# ATmega64A device description
Architecture: AVR8; Family: megaAVR
Registers are 8-bit, access not given, no defined reset value unless marked. A register's access mark holds for its fields unless they carry their own. Offsets are from the block's base; [hi:lo] are bit positions.

## USART0 — USART
Instances: USART0 0x00
0x29 UBRR0L — USART Baud Rate Register Low Byte
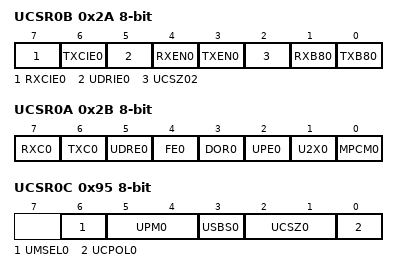
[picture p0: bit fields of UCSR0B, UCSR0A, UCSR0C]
0x2A UCSR0B — USART Control and Status Register B
  [7] RXCIE0 — RX Complete Interrupt Enable
  [6] TXCIE0 — TX Complete Interrupt Enable
  [5] UDRIE0 — USART Data register Empty Interrupt Enable
  [4] RXEN0 — Receiver Enable
  [3] TXEN0 — Transmitter Enable
  [2] UCSZ02 — Character Size
  [1] RXB80 — Receive Data Bit 8
  [0] TXB80 — Transmit Data Bit 8
0x2B UCSR0A — USART Control and Status Register A
  [7] RXC0 — USART Receive Complete
  [6] TXC0 — USART Transmitt Complete
  [5] UDRE0 — USART Data Register Empty
  [4] FE0 — Framing Error
  [3] DOR0 — Data overRun
  [2] UPE0 — Parity Error
  [1] U2X0 — Double the USART transmission speed
  [0] MPCM0 — Multi-processor Communication Mode
0x2C UDR0 — USART I/O Data Register
0x90 UBRR0H bits used 3:0 — USART Baud Rate Register Hight Byte
0x95 UCSR0C — USART Control and Status Register C
  [6] UMSEL0 — USART Mode Select
    0=Asynchronous Operation; 1=Synchronous Operation
  [5:4] UPM0 — Parity Mode Bits
    0=Disabled; 2=Enabled, Even Parity; 3=Enabled, Odd Parity
  [3] USBS0 — Stop Bit Select
    0=1-bit; 1=2-bit
  [2:1] UCSZ0 — Character Size
  [0] UCPOL0 — Clock Polarity

## USART1 — USART
Instances: USART1 0x00
0x98 UBRR1H bits used 3:0 — USART Baud Rate Register Hight Byte
0x99 UBRR1L — USART Baud Rate Register Low Byte
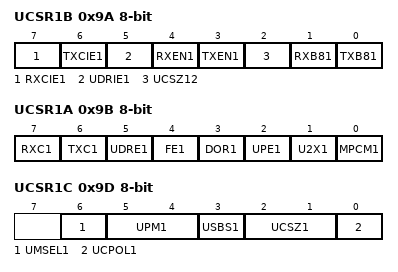
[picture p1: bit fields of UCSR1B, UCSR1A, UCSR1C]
0x9A UCSR1B — USART Control and Status Register B
  [7] RXCIE1 — RX Complete Interrupt Enable
  [6] TXCIE1 — TX Complete Interrupt Enable
  [5] UDRIE1 — USART Data register Empty Interrupt Enable
  [4] RXEN1 — Receiver Enable
  [3] TXEN1 — Transmitter Enable
  [2] UCSZ12 — Character Size
  [1] RXB81 — Receive Data Bit 8
  [0] TXB81 — Transmit Data Bit 8
0x9B UCSR1A — USART Control and Status Register A
  [7] RXC1 — USART Receive Complete
  [6] TXC1 — USART Transmitt Complete
  [5] UDRE1 — USART Data Register Empty
  [4] FE1 — Framing Error
  [3] DOR1 — Data overRun
  [2] UPE1 — Parity Error
  [1] U2X1 — Double the USART transmission speed
  [0] MPCM1 — Multi-processor Communication Mode
0x9C UDR1 — USART I/O Data Register
0x9D UCSR1C — USART Control and Status Register C
  [6] UMSEL1 — USART Mode Select
    0=Asynchronous Operation; 1=Synchronous Operation
  [5:4] UPM1 — Parity Mode Bits
    0=Disabled; 2=Enabled, Even Parity; 3=Enabled, Odd Parity
  [3] USBS1 — Stop Bit Select
    0=1-bit; 1=2-bit
  [2:1] UCSZ1 — Character Size
  [0] UCPOL1 — Clock Polarity

## CPU — CPU Registers
Instances: CPU 0x00
Parameters: CORE_VERSION=V2E
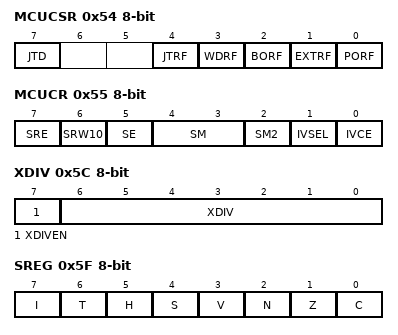
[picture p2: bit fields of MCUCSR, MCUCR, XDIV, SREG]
0x54 MCUCSR — MCU Control And Status Register
  [7] JTD — JTAG Interface Disable
  [4] JTRF — JTAG Reset Flag
  [3] WDRF — Watchdog Reset Flag
  [2] BORF — Brown-out Reset Flag
  [1] EXTRF — External Reset Flag
  [0] PORF — Power-on reset flag
0x55 MCUCR — MCU Control Register
  [7] SRE — External SRAM Enable
  [6] SRW10 — External SRAM Wait State Select
  [5] SE — Sleep Enable
  [4:3] SM — Sleep Mode Select
  [2] SM2 — Sleep Mode Select
    0=IDLE; 2=ADC (ADC Noise Reduction (If Available)); 4=PDOWN (Power Down); 6=PSAVE (Power Save); 5=STDBY (Standby); 7=ESTDBY (Extended Standby)
  [1] IVSEL — Interrupt Vector Select
  [0] IVCE — Interrupt Vector Change Enable
0x5C XDIV — XTAL Divide Control Register
  [7] XDIVEN — XTAL Divide Enable
  [6:0] XDIV — XTAl Divide Select Bits
0x5D SP 16-bit — Stack Pointer
0x5F SREG — Status Register
  [7] I — Global Interrupt Enable
  [6] T — Bit Copy Storage
  [5] H — Half Carry Flag
  [4] S — Sign Bit
  [3] V — Two's Complement Overflow Flag
  [2] N — Negative Flag
  [1] Z — Zero Flag
  [0] C — Carry Flag
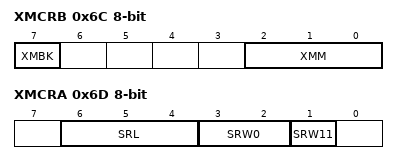
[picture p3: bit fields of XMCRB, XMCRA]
0x6C XMCRB — External Memory Control Register B
  [7] XMBK — External Memory Bus Keeper Enable
  [2:0] XMM — External Memory High Mask
0x6D XMCRA — External Memory Control Register A
  [6:4] SRL — Wait state page limit
    0=LS = N/A, US = 0x1100 - 0xFFFF; 1=LS = 0x1100 - 0x1FFF, US = 0x2000 - 0xFFFF; 2=LS = 0x1100 - 0x3FFF, US = 0x4000 - 0xFFFF; 3=LS = 0x1100 - 0x5FFF, US = 0x6000 - 0xFFFF; 4=LS = 0x1100 - 0x7FFF, US = 0x8000 - 0xFFFF; 5=LS = 0x1100 - 0x9FFF, US = 0xA000 - 0xFFFF; 6=LS = 0x1100 - 0xBFFF, US = 0xC000 - 0xFFFF; 7=LS = 0x1100 - 0xDFFF, US = 0xE000 - 0xFFFF
  [3:2] SRW0 — Wait state select bit lower page
    0=No wait-states; 1=Wait one cycle during read/write strobe; 2=Wait two cycles during read/write strobe; 3=Wait two cycles during read/write and wait one cycle before driving out new address
  [1] SRW11 — Wait state select bit upper page
0x6F OSCCAL — Oscillator Calibration Value
  [7:0] OSCCAL — Oscillator Calibration
Value list OSCCAL_VALUE_ADDRESSES: 0=1_0_MHz_; 1=2_0_MHz_; 2=4_0_MHz_; 3=8_0_MHz
